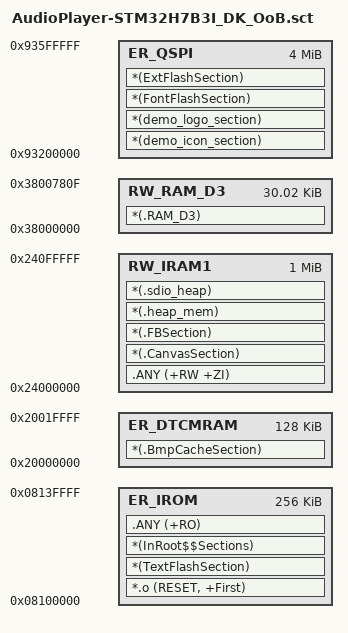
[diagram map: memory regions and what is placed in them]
; *************************************************************
; *** Scatter-Loading Description File generated by uVision ***
; *************************************************************


LR_IROM 0x08100000  0x40000     {    ; load region size_region
  ER_IROM 0x08100000 0x40000   {  ; load address = execution address
    *.o (RESET, +First)
    *(TextFlashSection)
    *(InRoot$$Sections)
     .ANY (+RO)
     }
   ER_DTCMRAM 0x20000000 0x20000  {     ; RW data
	    *(.BmpCacheSection)
     }	
	 
  RW_IRAM1 0x24000000 0x100000  {  ; RW data
    .ANY (+RW +ZI)
	*(.CanvasSection)
	*(.FBSection)
    *(.heap_mem) 
    *(.sdio_heap) 	
  }

   RW_RAM_D3 0x38000000 0x7810    { ; RW data
        *(.RAM_D3)
    } 
  }
    
 LR_QSPI 0x93200000  0x400000{    ; load region size_region
  ER_QSPI 0x93200000  0x400000{  
     *(demo_icon_section)    
     *(demo_logo_section) 
     *(FontFlashSection)
     *(ExtFlashSection)
	 }	 
	 
	 }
